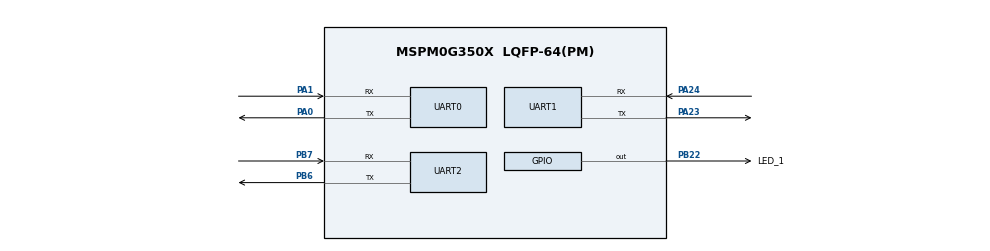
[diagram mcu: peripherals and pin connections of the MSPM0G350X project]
/**
 * @cliArgs --device "MSPM0G350X" --part "Default" --package "LQFP-64(PM)" --product "mspm0_sdk@2.05.01.00"
 * @versions {"tool":"1.21.0+3721"}
 */

/**
 * Import the modules used in this configuration.
 */
const GPIO   = scripting.addModule("/ti/driverlib/GPIO", {}, false);
const GPIO1  = GPIO.addInstance();
const SYSCTL = scripting.addModule("/ti/driverlib/SYSCTL");
const UART   = scripting.addModule("/ti/driverlib/UART", {}, false);
const UART0  = UART.addInstance();
const UART1  = UART.addInstance();
const UART2  = UART.addInstance();

/**
 * Write custom configuration values to the imported modules.
 */
const divider9       = system.clockTree["UDIV"];
divider9.divideValue = 2;

const gate7  = system.clockTree["MFCLKGATE"];
gate7.enable = true;

const multiplier2         = system.clockTree["PLL_QDIV"];
multiplier2.multiplyValue = 5;

const mux8       = system.clockTree["HSCLKMUX"];
mux8.inputSelect = "HSCLKMUX_SYSPLL0";

GPIO1.$name                         = "GPIO_GRP_0";
GPIO1.associatedPins[0].$name       = "LED_1";
GPIO1.associatedPins[0].pin.$assign = "PB22";

const Board = scripting.addModule("/ti/driverlib/Board", {}, false);

SYSCTL.forceDefaultClkConfig = true;
SYSCTL.clockTreeEn           = true;

UART0.$name                            = "maixcam";
UART0.uartClkSrc                       = "MFCLK";
UART0.targetBaudRate                   = 115200;
UART0.enableFIFO                       = true;
UART0.rxFifoThreshold                  = "DL_UART_RX_FIFO_LEVEL_1_2_FULL";
UART0.rxTimeoutValue                   = 15;
UART0.enabledInterrupts                = ["RX", "RX_TIMEOUT_ERROR"];
UART0.peripheral.$assign               = "UART0";
UART0.peripheral.rxPin.$assign         = "PA1";
UART0.peripheral.txPin.$assign         = "PA0";
UART0.txPinConfig.direction            = scripting.forceWrite("OUTPUT");
UART0.txPinConfig.hideOutputInversion  = scripting.forceWrite(false);
UART0.txPinConfig.onlyInternalResistor = scripting.forceWrite(false);
UART0.txPinConfig.passedPeripheralType = scripting.forceWrite("Digital");
UART0.txPinConfig.$name                = "ti_driverlib_gpio_GPIOPinGeneric2";
UART0.rxPinConfig.hideOutputInversion  = scripting.forceWrite(false);
UART0.rxPinConfig.onlyInternalResistor = scripting.forceWrite(false);
UART0.rxPinConfig.passedPeripheralType = scripting.forceWrite("Digital");
UART0.rxPinConfig.$name                = "ti_driverlib_gpio_GPIOPinGeneric3";

UART1.$name                            = "stepMotor2";
UART1.uartClkSrc                       = "MFCLK";
UART1.targetBaudRate                   = 115200;
UART1.enableFIFO                       = true;
UART1.peripheral.$assign               = "UART2";
UART1.peripheral.rxPin.$assign         = "PA24";
UART1.peripheral.txPin.$assign         = "PA23";
UART1.txPinConfig.direction            = scripting.forceWrite("OUTPUT");
UART1.txPinConfig.hideOutputInversion  = scripting.forceWrite(false);
UART1.txPinConfig.onlyInternalResistor = scripting.forceWrite(false);
UART1.txPinConfig.passedPeripheralType = scripting.forceWrite("Digital");
UART1.txPinConfig.$name                = "ti_driverlib_gpio_GPIOPinGeneric4";
UART1.rxPinConfig.hideOutputInversion  = scripting.forceWrite(false);
UART1.rxPinConfig.onlyInternalResistor = scripting.forceWrite(false);
UART1.rxPinConfig.passedPeripheralType = scripting.forceWrite("Digital");
UART1.rxPinConfig.$name                = "ti_driverlib_gpio_GPIOPinGeneric5";

UART2.$name                            = "stepMotor1";
UART2.uartClkSrc                       = "MFCLK";
UART2.targetBaudRate                   = 115200;
UART2.enableFIFO                       = true;
UART2.peripheral.$assign               = "UART1";
UART2.peripheral.rxPin.$assign         = "PB7";
UART2.peripheral.txPin.$assign         = "PB6";
UART2.txPinConfig.direction            = scripting.forceWrite("OUTPUT");
UART2.txPinConfig.hideOutputInversion  = scripting.forceWrite(false);
UART2.txPinConfig.onlyInternalResistor = scripting.forceWrite(false);
UART2.txPinConfig.passedPeripheralType = scripting.forceWrite("Digital");
UART2.txPinConfig.$name                = "ti_driverlib_gpio_GPIOPinGeneric6";
UART2.rxPinConfig.hideOutputInversion  = scripting.forceWrite(false);
UART2.rxPinConfig.onlyInternalResistor = scripting.forceWrite(false);
UART2.rxPinConfig.passedPeripheralType = scripting.forceWrite("Digital");
UART2.rxPinConfig.$name                = "ti_driverlib_gpio_GPIOPinGeneric7";

/**
 * Pinmux solution for unlocked pins/peripherals. This ensures that minor changes to the automatic solver in a future
 * version of the tool will not impact the pinmux you originally saw.  These lines can be completely deleted in order to
 * re-solve from scratch.
 */
Board.peripheral.$suggestSolution          = "DEBUGSS";
Board.peripheral.swclkPin.$suggestSolution = "PA20";
Board.peripheral.swdioPin.$suggestSolution = "PA19";
